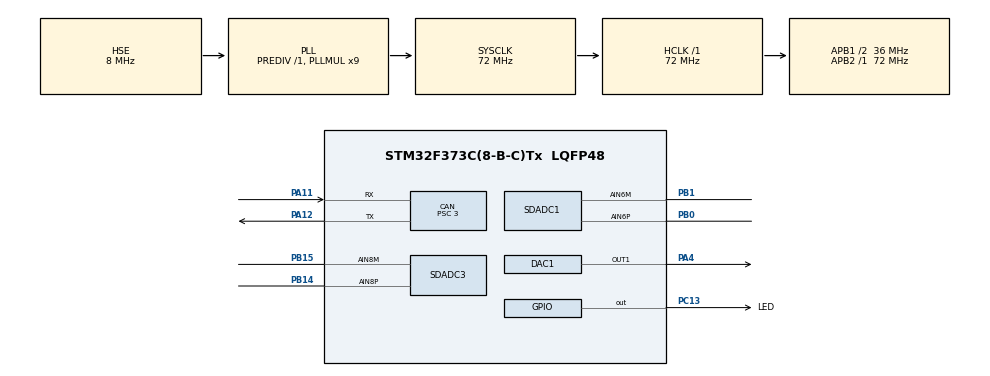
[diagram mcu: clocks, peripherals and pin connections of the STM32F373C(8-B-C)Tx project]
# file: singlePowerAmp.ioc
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CAN.ABOM=ENABLE
CAN.AWUM=ENABLE
CAN.BS1=CAN_BS1_9TQ
CAN.BS2=CAN_BS2_2TQ
CAN.CalculateTimeQuantum=83.33333333333334
CAN.Prescaler=3
CAN.TXFP=ENABLE
DAC1.DAC_Trigger=DAC_TRIGGER_NONE
Dma.DAC1_CH1.2.Direction=DMA_MEMORY_TO_PERIPH
Dma.DAC1_CH1.2.Instance=DMA1_Channel3
Dma.DAC1_CH1.2.MemDataAlignment=DMA_MDATAALIGN_HALFWORD
Dma.DAC1_CH1.2.MemInc=DMA_MINC_DISABLE
Dma.DAC1_CH1.2.Mode=DMA_CIRCULAR
Dma.DAC1_CH1.2.PeriphDataAlignment=DMA_PDATAALIGN_HALFWORD
Dma.DAC1_CH1.2.PeriphInc=DMA_PINC_DISABLE
Dma.DAC1_CH1.2.Priority=DMA_PRIORITY_LOW
Dma.Request0=SDADC3
Dma.Request1=SDADC1
Dma.Request2=DAC1_CH1
Dma.SDADC1.1.Direction=DMA_PERIPH_TO_MEMORY
Dma.SDADC1.1.Instance=DMA2_Channel3
Dma.SDADC1.1.MemDataAlignment=DMA_MDATAALIGN_HALFWORD
Dma.SDADC1.1.MemInc=DMA_MINC_ENABLE
Dma.SDADC1.1.Mode=DMA_NORMAL
Dma.SDADC1.1.PeriphDataAlignment=DMA_PDATAALIGN_HALFWORD
Dma.SDADC1.1.PeriphInc=DMA_PINC_DISABLE
Dma.SDADC1.1.Priority=DMA_PRIORITY_MEDIUM
Dma.SDADC3.0.Direction=DMA_PERIPH_TO_MEMORY
Dma.SDADC3.0.Instance=DMA2_Channel5
Dma.SDADC3.0.MemDataAlignment=DMA_MDATAALIGN_WORD
Dma.SDADC3.0.MemInc=DMA_MINC_ENABLE
Dma.SDADC3.0.Mode=DMA_CIRCULAR
Dma.SDADC3.0.PeriphDataAlignment=DMA_PDATAALIGN_WORD
Dma.SDADC3.0.PeriphInc=DMA_PINC_DISABLE
Dma.SDADC3.0.Priority=DMA_PRIORITY_MEDIUM
FREERTOS.Tasks01=defaultTask,0,128,StartDefaultTask,Default,NULL
Mcu.Family=STM32F3
Mcu.Name=STM32F373C(8-B-C)Tx
Mcu.Package=LQFP48
NVIC.CAN_RX0_IRQn=true\:5\:0\:false\:false\:true\:true\:true\:true
NVIC.CAN_RX1_IRQn=true\:5\:0\:false\:false\:true\:true\:true\:true
NVIC.DMA1_Channel3_IRQn=true\:5\:0\:false\:false\:true\:true\:false\:true
NVIC.DMA2_Channel3_IRQn=true\:5\:0\:false\:false\:true\:true\:false\:true
NVIC.DMA2_Channel5_IRQn=true\:5\:0\:false\:false\:true\:true\:false\:true
NVIC.PriorityGroup=NVIC_PRIORITYGROUP_4
NVIC.TIM19_IRQn=true\:0\:0\:false\:false\:true\:false\:false\:true
NVIC.TimeBase=TIM19_IRQn
NVIC.TimeBaseIP=TIM19
PA11.Mode=Master
PA11.Signal=CAN_RX
PA12.Mode=Master
PA12.Signal=CAN_TX
PA13.Mode=Serial_Wire
PA13.Signal=SYS_JTMS-SWDIO
PA14.Mode=Serial_Wire
PA14.Signal=SYS_JTCK-SWCLK
PA4.Signal=COMP_DAC11_group
PB0.Mode=IN6-Differential
PB0.Signal=SDADC1_AIN6P
PB1.Mode=IN6-Differential
PB1.Signal=SDADC1_AIN6M
PB14.Mode=IN8-Differential
PB14.Signal=SDADC3_AIN8P
PB15.Mode=IN8-Differential
PB15.Signal=SDADC3_AIN8M
PC13.GPIO_Label=LED
PC13.Signal=GPIO_Output
PC14-OSC32_IN.Mode=LSE-External-Oscillator
PC14-OSC32_IN.Signal=RCC_OSC32_IN
PC15-OSC32_OUT.Mode=LSE-External-Oscillator
PC15-OSC32_OUT.Signal=RCC_OSC32_OUT
PF0-OSC_IN.Mode=HSE-External-Oscillator
PF0-OSC_IN.Signal=RCC_OSC_IN
PF1-OSC_OUT.Mode=HSE-External-Oscillator
PF1-OSC_OUT.Signal=RCC_OSC_OUT
ProjectManager.HeapSize=0x200
ProjectManager.StackSize=0x400
ProjectManager.TargetToolchain=Makefile
RCC.AHBFreq_Value=72000000
RCC.APB1CLKDivider=RCC_HCLK_DIV2
RCC.APB1Freq_Value=36000000
RCC.APB1TimFreq_Value=72000000
RCC.APB2Freq_Value=72000000
RCC.APB2TimFreq_Value=72000000
RCC.CortexFreq_Value=72000000
RCC.HCLKFreq_Value=72000000
RCC.HSE_VALUE=8000000
RCC.HSI_VALUE=8000000
RCC.PLLMUL=RCC_PLL_MUL9
RCC.PLLSourceVirtual=RCC_PLLSOURCE_HSE
RCC.PRESCALERUSB=RCC_USBCLKSOURCE_PLL_DIV1_5
RCC.SDADCPresc=RCC_SDADCSYSCLK_DIV12
RCC.SYSCLKFreq_VALUE=72000000
RCC.SYSCLKSource=RCC_SYSCLKSOURCE_PLLCLK
RCC.USBFreq_Value=48000000
SDADC1.Channel-49\#ChannelRegularConversion=SDADC_CHANNEL_6
SDADC1.ConfIndex-49\#ChannelRegularConversion=SDADC_CONF_INDEX_0
SDADC1.ContinuousMode=SDADC_CONTINUOUS_CONV_ON
SDADC1.EnableRegularconversion=ENABLE
SDADC1.FastConversionMode=SDADC_FAST_CONV_ENABLE
SDADC1.NbrOfConversionFlag=1
SDADC1.ReferenceVoltage=SDADC_VREF_VREFINT2
SDADC3.Channel-0\#ChannelRegularConversion=SDADC_CHANNEL_8
SDADC3.ConfIndex-0\#ChannelRegularConversion=SDADC_CONF_INDEX_0
SDADC3.ContinuousMode=SDADC_CONTINUOUS_CONV_ON
SDADC3.EnableRegularconversion=ENABLE
SDADC3.FastConversionMode=SDADC_FAST_CONV_ENABLE
SDADC3.NbrOfConversionFlag=1
SDADC3.ReferenceVoltage=SDADC_VREF_VREFINT2
SH.COMP_DAC11_group.0=DAC1_OUT1,DAC_OUT1
VP_FREERTOS_VS_CMSIS_V1.Mode=CMSIS_V1
VP_SDADC1_CONF0.Mode=ConfigZero
VP_SDADC3_CONF0.Mode=ConfigZero
VP_SYS_VS_tim19.Mode=TIM19
board=custom

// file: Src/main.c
/* USER CODE BEGIN Header */
/**
  ******************************************************************************
  * @file           : main.c
  * @brief          : Main program body
  ******************************************************************************
  ** This notice applies to any and all portions of this file
  * that are not between comment pairs USER CODE BEGIN and
  * USER CODE END. Other portions of this file, whether
  * inserted by the user or by software development tools
  * are owned by their respective copyright owners.
  *
  * COPYRIGHT(c) 2019 STMicroelectronics
  *
  * Redistribution and use in source and binary forms, with or without modification,
  * are permitted provided that the following conditions are met:
  *   1. Redistributions of source code must retain the above copyright notice,
  *      this list of conditions and the following disclaimer.
  *   2. Redistributions in binary form must reproduce the above copyright notice,
  *      this list of conditions and the following disclaimer in the documentation
  *      and/or other materials provided with the distribution.
  *   3. Neither the name of STMicroelectronics nor the names of its contributors
  *      may be used to endorse or promote products derived from this software
  *      without specific prior written permission.
  *
  * THIS SOFTWARE IS PROVIDED BY THE COPYRIGHT HOLDERS AND CONTRIBUTORS "AS IS"
  * AND ANY EXPRESS OR IMPLIED WARRANTIES, INCLUDING, BUT NOT LIMITED TO, THE
  * IMPLIED WARRANTIES OF MERCHANTABILITY AND FITNESS FOR A PARTICULAR PURPOSE ARE
  * DISCLAIMED. IN NO EVENT SHALL THE COPYRIGHT HOLDER OR CONTRIBUTORS BE LIABLE
  * FOR ANY DIRECT, INDIRECT, INCIDENTAL, SPECIAL, EXEMPLARY, OR CONSEQUENTIAL
  * DAMAGES (INCLUDING, BUT NOT LIMITED TO, PROCUREMENT OF SUBSTITUTE GOODS OR
  * SERVICES; LOSS OF USE, DATA, OR PROFITS; OR BUSINESS INTERRUPTION) HOWEVER
  * CAUSED AND ON ANY THEORY OF LIABILITY, WHETHER IN CONTRACT, STRICT LIABILITY,
  * OR TORT (INCLUDING NEGLIGENCE OR OTHERWISE) ARISING IN ANY WAY OUT OF THE USE
  * OF THIS SOFTWARE, EVEN IF ADVISED OF THE POSSIBILITY OF SUCH DAMAGE.
  *
  ******************************************************************************
  */
/* USER CODE END Header */

#include "main.h"
#include "cmsis_os.h"
#include "can.h"
#include "dac.h"
#include "dma.h"
#include "sdadc.h"
#include "gpio.h"

/* USER CODE BEGIN Includes */
#include "sampling.h"
/* USER CODE END Includes */

void SystemClock_Config(void);
void MX_FREERTOS_Init(void);

int main(void)
{

  /* MCU Configuration--------------------------------------------------------*/

  /* Reset of all peripherals, Initializes the Flash interface and the Systick. */
  HAL_Init();

  /* Configure the system clock */
  SystemClock_Config();

  /* Initialize all configured peripherals */
  MX_GPIO_Init();
  MX_DMA_Init();
  MX_SDADC3_Init();
  MX_SDADC1_Init();
  MX_DAC1_Init();
  MX_CAN_Init();
  /* USER CODE BEGIN 2 */
  HAL_CAN_Start(&hcan);
  SamplingStart();
  /* USER CODE END 2 */

  /* Call init function for freertos objects (in freertos.c) */
  MX_FREERTOS_Init();

  /* Start scheduler */
  osKernelStart();

  /* We should never get here as control is now taken by the scheduler */

  /* Infinite loop */
  while (1)
  {
  }

    /* USER CODE BEGIN 3 */
  // HAL_CAN_GetRxMessage(hcan, )
  /* USER CODE END 3 */
}

void SystemClock_Config(void)
{
  RCC_OscInitTypeDef RCC_OscInitStruct = {0};
  RCC_ClkInitTypeDef RCC_ClkInitStruct = {0};
  RCC_PeriphCLKInitTypeDef PeriphClkInit = {0};

  /** Initializes the CPU, AHB and APB busses clocks
  */
  RCC_OscInitStruct.OscillatorType = RCC_OSCILLATORTYPE_HSE;
  RCC_OscInitStruct.HSEState = RCC_HSE_ON;
  RCC_OscInitStruct.HSEPredivValue = RCC_HSE_PREDIV_DIV1;
  RCC_OscInitStruct.HSIState = RCC_HSI_ON;
  RCC_OscInitStruct.PLL.PLLState = RCC_PLL_ON;
  RCC_OscInitStruct.PLL.PLLSource = RCC_PLLSOURCE_HSE;
  RCC_OscInitStruct.PLL.PLLMUL = RCC_PLL_MUL9;
  if (HAL_RCC_OscConfig(&RCC_OscInitStruct) != HAL_OK)
  {
    Error_Handler();
  }
  /** Initializes the CPU, AHB and APB busses clocks
  */
  RCC_ClkInitStruct.ClockType = RCC_CLOCKTYPE_HCLK|RCC_CLOCKTYPE_SYSCLK
                              |RCC_CLOCKTYPE_PCLK1|RCC_CLOCKTYPE_PCLK2;
  RCC_ClkInitStruct.SYSCLKSource = RCC_SYSCLKSOURCE_PLLCLK;
  RCC_ClkInitStruct.AHBCLKDivider = RCC_SYSCLK_DIV1;
  RCC_ClkInitStruct.APB1CLKDivider = RCC_HCLK_DIV2;
  RCC_ClkInitStruct.APB2CLKDivider = RCC_HCLK_DIV1;

  if (HAL_RCC_ClockConfig(&RCC_ClkInitStruct, FLASH_LATENCY_2) != HAL_OK)
  {
    Error_Handler();
  }
  PeriphClkInit.PeriphClockSelection = RCC_PERIPHCLK_SDADC;
  PeriphClkInit.SdadcClockSelection = RCC_SDADCSYSCLK_DIV12;
  if (HAL_RCCEx_PeriphCLKConfig(&PeriphClkInit) != HAL_OK)
  {
    Error_Handler();
  }
  HAL_PWREx_EnableSDADC(PWR_SDADC_ANALOG1);
  HAL_PWREx_EnableSDADC(PWR_SDADC_ANALOG3);
}

void HAL_TIM_PeriodElapsedCallback(TIM_HandleTypeDef *htim)
{
  if (htim->Instance == TIM19) {
    HAL_IncTick();
  }
}

void Error_Handler(void)
{
}

/************************ (C) COPYRIGHT STMicroelectronics *****END OF FILE****/

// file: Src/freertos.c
/* USER CODE BEGIN Header */
/**
  ******************************************************************************
  * File Name          : freertos.c
  * Description        : Code for freertos applications
  ******************************************************************************
  * @attention
  *
  * <h2><center>&copy; Copyright (c) 2019 STMicroelectronics.
  * All rights reserved.</center></h2>
  *
  * This software component is licensed by ST under Ultimate Liberty license
  * SLA0044, the "License"; You may not use this file except in compliance with
  * the License. You may obtain a copy of the License at:
  *                             www.st.com/SLA0044
  *
  ******************************************************************************
  */
/* USER CODE END Header */

#include "FreeRTOS.h"
#include "task.h"
#include "main.h"
#include "cmsis_os.h"

/* USER CODE BEGIN Includes */
#include "can.h"
#include "sampling.h"
/* USER CODE END Includes */

osThreadId defaultTaskHandle;

void StartDefaultTask(void const * argument);

void MX_FREERTOS_Init(void); /* (MISRA C 2004 rule 8.1) */

void MX_FREERTOS_Init(void) {

  /* Create the thread(s) */
  /* definition and creation of defaultTask */
  osThreadDef(defaultTask, StartDefaultTask, osPriorityNormal, 0, 128);
  defaultTaskHandle = osThreadCreate(osThread(defaultTask), NULL);

}

void StartDefaultTask(void const * argument)
{

  /* USER CODE BEGIN StartDefaultTask */
  /* Infinite loop */
  while (1)
  {
    HAL_GPIO_TogglePin(LED_GPIO_Port, LED_Pin);
    osDelay(100);
  }
  /* USER CODE END StartDefaultTask */
}

/************************ (C) COPYRIGHT STMicroelectronics *****END OF FILE****/
